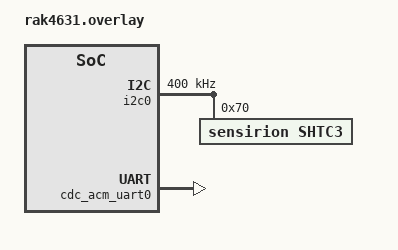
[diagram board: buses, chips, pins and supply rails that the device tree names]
/ {
	chosen {
		zephyr,console = &cdc_acm_uart0;
	};
};

&i2c0 {
	status = "okay";
	clock-frequency = <I2C_BITRATE_FAST>;
	shtc3@70 {
		compatible = "sensirion,shtc3", "sensirion,shtcx";
		reg = <0x70>;
		measure-mode = "normal";
	};
};

&reg1 {
	regulator-initial-mode = <NRF5X_REG_MODE_DCDC>;
};

&zephyr_udc0 {
	cdc_acm_uart0: cdc_acm_uart0 {
		compatible = "zephyr,cdc-acm-uart";
	};
};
